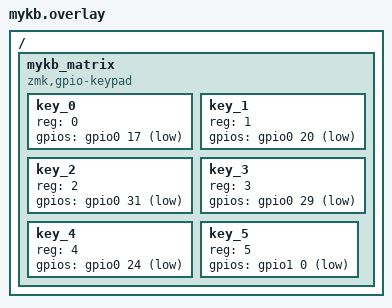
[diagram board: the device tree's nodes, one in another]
/ {
	mykb_matrix {
		compatible = "zmk,gpio-keypad";
		#address-cells = <1>;
		#size-cells = <0>;

		key_0 {
			reg = <0>;
			gpios = <&gpio0 17 GPIO_ACTIVE_LOW>;
		};
		key_1 {
			reg = <1>;
			gpios = <&gpio0 20 GPIO_ACTIVE_LOW>;
		};
		key_2 {
			reg = <2>;
			gpios = <&gpio0 31 GPIO_ACTIVE_LOW>;
		};
		key_3 {
			reg = <3>;
			gpios = <&gpio0 29 GPIO_ACTIVE_LOW>;
		};
		key_4 {
			reg = <4>;
			gpios = <&gpio0 24 GPIO_ACTIVE_LOW>;
		};
		key_5 {
			reg = <5>;
			gpios = <&gpio1 0 GPIO_ACTIVE_LOW>;
		};
	};
};
